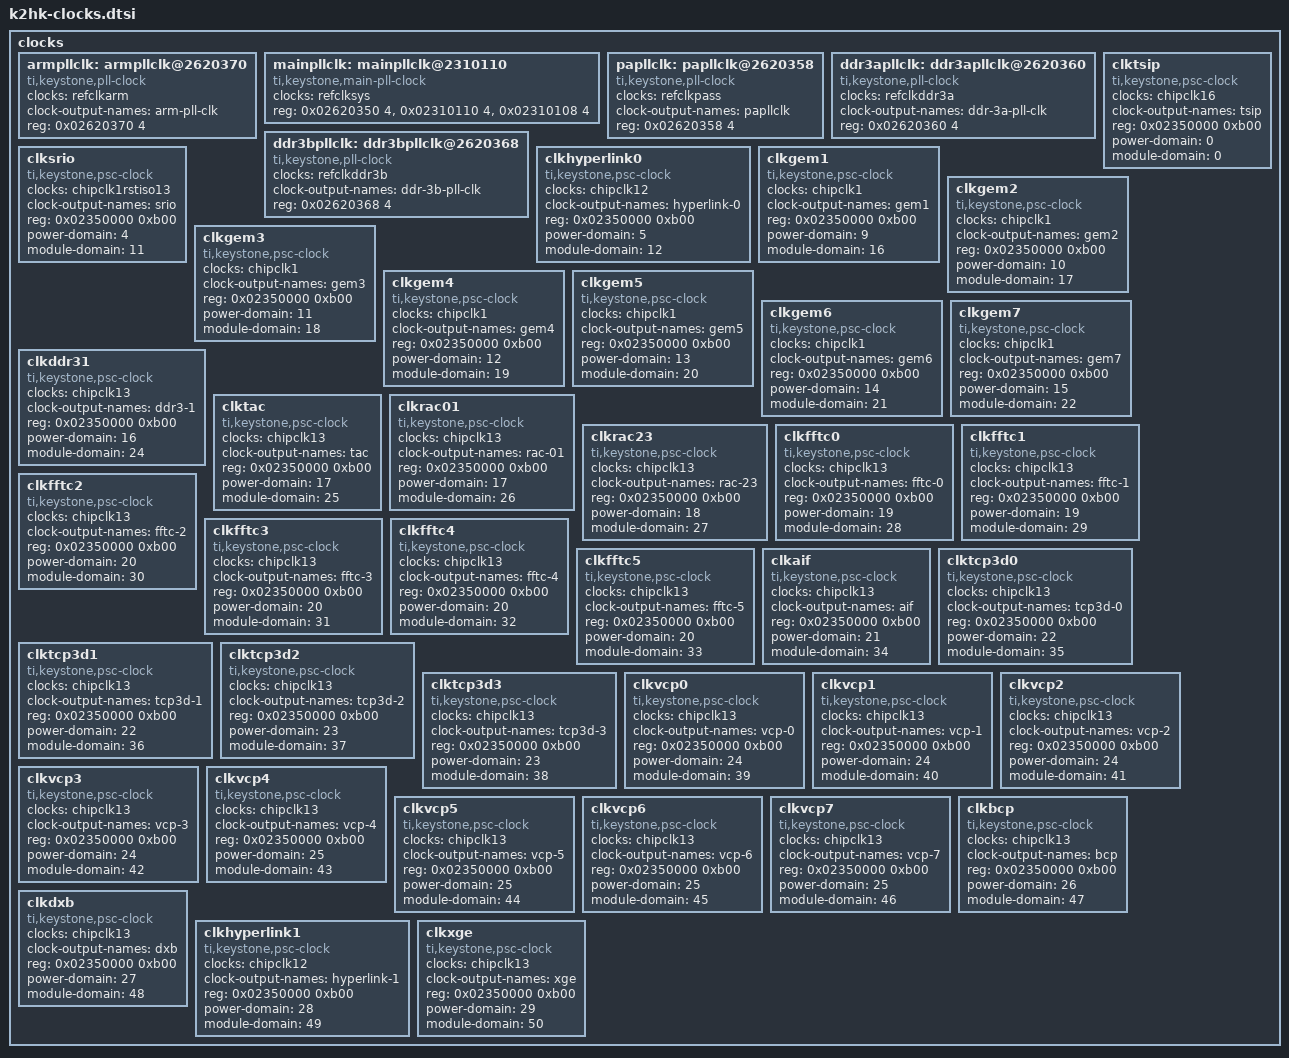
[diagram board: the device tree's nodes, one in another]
/*
 * Copyright 2013-2014 Texas Instruments, Inc.
 *
 * Keystone 2 Kepler/Hawking SoC clock nodes
 *
 * This program is free software; you can redistribute it and/or modify
 * it under the terms of the GNU General Public License version 2 as
 * published by the Free Software Foundation.
 */

clocks {
	armpllclk: armpllclk@2620370 {
		#clock-cells = <0>;
		compatible = "ti,keystone,pll-clock";
		clocks = <&refclkarm>;
		clock-output-names = "arm-pll-clk";
		reg = <0x02620370 4>;
		reg-names = "control";
	};

	mainpllclk: mainpllclk@2310110 {
		#clock-cells = <0>;
		compatible = "ti,keystone,main-pll-clock";
		clocks = <&refclksys>;
		reg = <0x02620350 4>, <0x02310110 4>, <0x02310108 4>;
		reg-names = "control", "multiplier", "post-divider";
	};

	papllclk: papllclk@2620358 {
		#clock-cells = <0>;
		compatible = "ti,keystone,pll-clock";
		clocks = <&refclkpass>;
		clock-output-names = "papllclk";
		reg = <0x02620358 4>;
		reg-names = "control";
	};

	ddr3apllclk: ddr3apllclk@2620360 {
		#clock-cells = <0>;
		compatible = "ti,keystone,pll-clock";
		clocks = <&refclkddr3a>;
		clock-output-names = "ddr-3a-pll-clk";
		reg = <0x02620360 4>;
		reg-names = "control";
	};

	ddr3bpllclk: ddr3bpllclk@2620368 {
		#clock-cells = <0>;
		compatible = "ti,keystone,pll-clock";
		clocks = <&refclkddr3b>;
		clock-output-names = "ddr-3b-pll-clk";
		reg = <0x02620368 4>;
		reg-names = "control";
	};

	clktsip: clktsip {
		#clock-cells = <0>;
		compatible = "ti,keystone,psc-clock";
		clocks = <&chipclk16>;
		clock-output-names = "tsip";
		reg = <0x02350000 0xb00>;
		power-domain = <0>;
		module-domain = <0>;
	};

	clksrio: clksrio {
		#clock-cells = <0>;
		compatible = "ti,keystone,psc-clock";
		clocks = <&chipclk1rstiso13>;
		clock-output-names = "srio";
		reg = <0x02350000 0xb00>;
		power-domain = <4>;
		module-domain = <11>;
	};

	clkhyperlink0: clkhyperlink0 {
		#clock-cells = <0>;
		compatible = "ti,keystone,psc-clock";
		clocks = <&chipclk12>;
		clock-output-names = "hyperlink-0";
		reg = <0x02350000 0xb00>;
		power-domain = <5>;
		module-domain = <12>;
	};

	clkgem1: clkgem1 {
		#clock-cells = <0>;
		compatible = "ti,keystone,psc-clock";
		clocks = <&chipclk1>;
		clock-output-names = "gem1";
		reg = <0x02350000 0xb00>;
		power-domain = <9>;
		module-domain = <16>;
	};

	clkgem2: clkgem2 {
		#clock-cells = <0>;
		compatible = "ti,keystone,psc-clock";
		clocks = <&chipclk1>;
		clock-output-names = "gem2";
		reg = <0x02350000 0xb00>;
		power-domain = <10>;
		module-domain = <17>;
	};

	clkgem3: clkgem3 {
		#clock-cells = <0>;
		compatible = "ti,keystone,psc-clock";
		clocks = <&chipclk1>;
		clock-output-names = "gem3";
		reg = <0x02350000 0xb00>;
		power-domain = <11>;
		module-domain = <18>;
	};

	clkgem4: clkgem4 {
		#clock-cells = <0>;
		compatible = "ti,keystone,psc-clock";
		clocks = <&chipclk1>;
		clock-output-names = "gem4";
		reg = <0x02350000 0xb00>;
		power-domain = <12>;
		module-domain = <19>;
	};

	clkgem5: clkgem5 {
		#clock-cells = <0>;
		compatible = "ti,keystone,psc-clock";
		clocks = <&chipclk1>;
		clock-output-names = "gem5";
		reg = <0x02350000 0xb00>;
		power-domain = <13>;
		module-domain = <20>;
	};

	clkgem6: clkgem6 {
		#clock-cells = <0>;
		compatible = "ti,keystone,psc-clock";
		clocks = <&chipclk1>;
		clock-output-names = "gem6";
		reg = <0x02350000 0xb00>;
		power-domain = <14>;
		module-domain = <21>;
	};

	clkgem7: clkgem7 {
		#clock-cells = <0>;
		compatible = "ti,keystone,psc-clock";
		clocks = <&chipclk1>;
		clock-output-names = "gem7";
		reg = <0x02350000 0xb00>;
		power-domain = <15>;
		module-domain = <22>;
	};

	clkddr31: clkddr31 {
		#clock-cells = <0>;
		compatible = "ti,keystone,psc-clock";
		clocks = <&chipclk13>;
		clock-output-names = "ddr3-1";
		reg = <0x02350000 0xb00>;
		power-domain = <16>;
		module-domain = <24>;
	};

	clktac: clktac {
		#clock-cells = <0>;
		compatible = "ti,keystone,psc-clock";
		clocks = <&chipclk13>;
		clock-output-names = "tac";
		reg = <0x02350000 0xb00>;
		power-domain = <17>;
		module-domain = <25>;
	};

	clkrac01: clkrac01 {
		#clock-cells = <0>;
		compatible = "ti,keystone,psc-clock";
		clocks = <&chipclk13>;
		clock-output-names = "rac-01";
		reg = <0x02350000 0xb00>;
		power-domain = <17>;
		module-domain = <26>;
	};

	clkrac23: clkrac23 {
		#clock-cells = <0>;
		compatible = "ti,keystone,psc-clock";
		clocks = <&chipclk13>;
		clock-output-names = "rac-23";
		reg = <0x02350000 0xb00>;
		power-domain = <18>;
		module-domain = <27>;
	};

	clkfftc0: clkfftc0 {
		#clock-cells = <0>;
		compatible = "ti,keystone,psc-clock";
		clocks = <&chipclk13>;
		clock-output-names = "fftc-0";
		reg = <0x02350000 0xb00>;
		power-domain = <19>;
		module-domain = <28>;
	};

	clkfftc1: clkfftc1 {
		#clock-cells = <0>;
		compatible = "ti,keystone,psc-clock";
		clocks = <&chipclk13>;
		clock-output-names = "fftc-1";
		reg = <0x02350000 0xb00>;
		power-domain = <19>;
		module-domain = <29>;
	};

	clkfftc2: clkfftc2 {
		#clock-cells = <0>;
		compatible = "ti,keystone,psc-clock";
		clocks = <&chipclk13>;
		clock-output-names = "fftc-2";
		reg = <0x02350000 0xb00>;
		power-domain = <20>;
		module-domain = <30>;
	};

	clkfftc3: clkfftc3 {
		#clock-cells = <0>;
		compatible = "ti,keystone,psc-clock";
		clocks = <&chipclk13>;
		clock-output-names = "fftc-3";
		reg = <0x02350000 0xb00>;
		power-domain = <20>;
		module-domain = <31>;
	};

	clkfftc4: clkfftc4 {
		#clock-cells = <0>;
		compatible = "ti,keystone,psc-clock";
		clocks = <&chipclk13>;
		clock-output-names = "fftc-4";
		reg = <0x02350000 0xb00>;
		power-domain = <20>;
		module-domain = <32>;
	};

	clkfftc5: clkfftc5 {
		#clock-cells = <0>;
		compatible = "ti,keystone,psc-clock";
		clocks = <&chipclk13>;
		clock-output-names = "fftc-5";
		reg = <0x02350000 0xb00>;
		power-domain = <20>;
		module-domain = <33>;
	};

	clkaif: clkaif {
		#clock-cells = <0>;
		compatible = "ti,keystone,psc-clock";
		clocks = <&chipclk13>;
		clock-output-names = "aif";
		reg = <0x02350000 0xb00>;
		power-domain = <21>;
		module-domain = <34>;
	};

	clktcp3d0: clktcp3d0 {
		#clock-cells = <0>;
		compatible = "ti,keystone,psc-clock";
		clocks = <&chipclk13>;
		clock-output-names = "tcp3d-0";
		reg = <0x02350000 0xb00>;
		power-domain = <22>;
		module-domain = <35>;
	};

	clktcp3d1: clktcp3d1 {
		#clock-cells = <0>;
		compatible = "ti,keystone,psc-clock";
		clocks = <&chipclk13>;
		clock-output-names = "tcp3d-1";
		reg = <0x02350000 0xb00>;
		power-domain = <22>;
		module-domain = <36>;
	};

	clktcp3d2: clktcp3d2 {
		#clock-cells = <0>;
		compatible = "ti,keystone,psc-clock";
		clocks = <&chipclk13>;
		clock-output-names = "tcp3d-2";
		reg = <0x02350000 0xb00>;
		power-domain = <23>;
		module-domain = <37>;
	};

	clktcp3d3: clktcp3d3 {
		#clock-cells = <0>;
		compatible = "ti,keystone,psc-clock";
		clocks = <&chipclk13>;
		clock-output-names = "tcp3d-3";
		reg = <0x02350000 0xb00>;
		power-domain = <23>;
		module-domain = <38>;
	};

	clkvcp0: clkvcp0 {
		#clock-cells = <0>;
		compatible = "ti,keystone,psc-clock";
		clocks = <&chipclk13>;
		clock-output-names = "vcp-0";
		reg = <0x02350000 0xb00>;
		power-domain = <24>;
		module-domain = <39>;
	};

	clkvcp1: clkvcp1 {
		#clock-cells = <0>;
		compatible = "ti,keystone,psc-clock";
		clocks = <&chipclk13>;
		clock-output-names = "vcp-1";
		reg = <0x02350000 0xb00>;
		power-domain = <24>;
		module-domain = <40>;
	};

	clkvcp2: clkvcp2 {
		#clock-cells = <0>;
		compatible = "ti,keystone,psc-clock";
		clocks = <&chipclk13>;
		clock-output-names = "vcp-2";
		reg = <0x02350000 0xb00>;
		power-domain = <24>;
		module-domain = <41>;
	};

	clkvcp3: clkvcp3 {
		#clock-cells = <0>;
		compatible = "ti,keystone,psc-clock";
		clocks = <&chipclk13>;
		clock-output-names = "vcp-3";
		reg = <0x02350000 0xb00>;
		power-domain = <24>;
		module-domain = <42>;
	};

	clkvcp4: clkvcp4 {
		#clock-cells = <0>;
		compatible = "ti,keystone,psc-clock";
		clocks = <&chipclk13>;
		clock-output-names = "vcp-4";
		reg = <0x02350000 0xb00>;
		power-domain = <25>;
		module-domain = <43>;
	};

	clkvcp5: clkvcp5 {
		#clock-cells = <0>;
		compatible = "ti,keystone,psc-clock";
		clocks = <&chipclk13>;
		clock-output-names = "vcp-5";
		reg = <0x02350000 0xb00>;
		power-domain = <25>;
		module-domain = <44>;
	};

	clkvcp6: clkvcp6 {
		#clock-cells = <0>;
		compatible = "ti,keystone,psc-clock";
		clocks = <&chipclk13>;
		clock-output-names = "vcp-6";
		reg = <0x02350000 0xb00>;
		power-domain = <25>;
		module-domain = <45>;
	};

	clkvcp7: clkvcp7 {
		#clock-cells = <0>;
		compatible = "ti,keystone,psc-clock";
		clocks = <&chipclk13>;
		clock-output-names = "vcp-7";
		reg = <0x02350000 0xb00>;
		power-domain = <25>;
		module-domain = <46>;
	};

	clkbcp: clkbcp {
		#clock-cells = <0>;
		compatible = "ti,keystone,psc-clock";
		clocks = <&chipclk13>;
		clock-output-names = "bcp";
		reg = <0x02350000 0xb00>;
		power-domain = <26>;
		module-domain = <47>;
	};

	clkdxb: clkdxb {
		#clock-cells = <0>;
		compatible = "ti,keystone,psc-clock";
		clocks = <&chipclk13>;
		clock-output-names = "dxb";
		reg = <0x02350000 0xb00>;
		power-domain = <27>;
		module-domain = <48>;
	};

	clkhyperlink1: clkhyperlink1 {
		#clock-cells = <0>;
		compatible = "ti,keystone,psc-clock";
		clocks = <&chipclk12>;
		clock-output-names = "hyperlink-1";
		reg = <0x02350000 0xb00>;
		power-domain = <28>;
		module-domain = <49>;
	};

	clkxge: clkxge {
		#clock-cells = <0>;
		compatible = "ti,keystone,psc-clock";
		clocks = <&chipclk13>;
		clock-output-names = "xge";
		reg = <0x02350000 0xb00>;
		power-domain = <29>;
		module-domain = <50>;
	};
};
